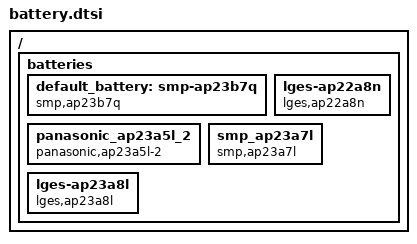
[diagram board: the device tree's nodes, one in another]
/* Copyright 2025 The ChromiumOS Authors
 * Use of this source code is governed by a BSD-style license that can be
 * found in the LICENSE file.
 */

/ {
    batteries {
		default_battery: smp-ap23b7q {
			compatible = "smp,ap23b7q", "battery-smart";
		};
		panasonic_ap23a5l_2 {
			compatible = "panasonic,ap23a5l-2", "battery-smart";
		};
		lges-ap22a8n {
			compatible = "lges,ap22a8n", "battery-smart";
		};
		smp_ap23a7l {
			compatible = "smp,ap23a7l", "battery-smart";
		};
		lges-ap23a8l {
			compatible = "lges,ap23a8l", "battery-smart";
		};
	};
};
